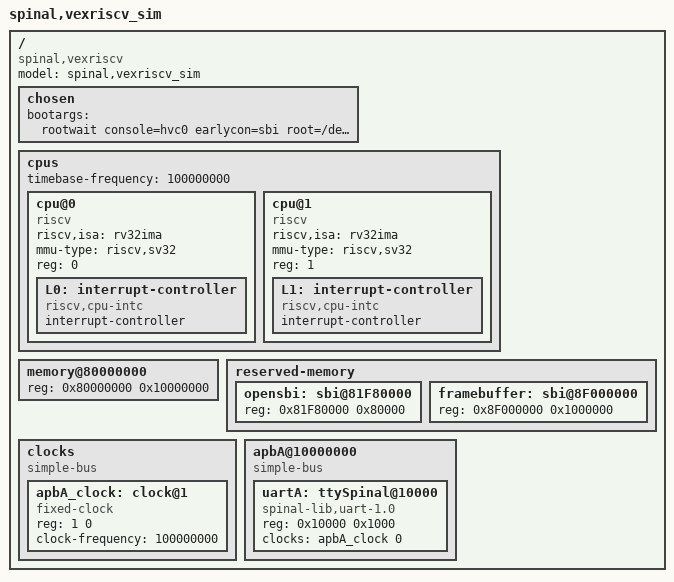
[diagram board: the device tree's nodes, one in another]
/dts-v1/;
#include <dt-bindings/gpio/gpio.h>
#include <dt-bindings/input/input.h>
#include <dt-bindings/interrupt-controller/irq.h>

/ {
    #address-cells = <0x1>;
    #size-cells = <0x1>;
    compatible = "spinal,vexriscv";
    model = "spinal,vexriscv_sim";

    chosen {
        bootargs = "rootwait console=hvc0  earlycon=sbi root=/dev/mmcblk0p2 init=/sbin/init mmc_core.use_spi_crc=0 loglevel=7";  //ignore_loglevel rng_core.default_quality=1000 random.trust_cpu=on
    };

    cpus {
        #address-cells = <0x1>;
        #size-cells = <0x0>;
        timebase-frequency = <100000000>;
        cpu@0 {
            device_type = "cpu";
            compatible = "riscv";
            riscv,isa = "rv32ima";
            mmu-type = "riscv,sv32";
            reg = <0>;
            status = "okay";
            L0: interrupt-controller {
                #interrupt-cells = <0x00000001>;
                interrupt-controller;
                compatible = "riscv,cpu-intc";
            };
        };
        cpu@1 {
            device_type = "cpu";
            compatible = "riscv";
            riscv,isa = "rv32ima";
            mmu-type = "riscv,sv32";
            reg = <1>;
            status = "okay";
            L1: interrupt-controller {
                #interrupt-cells = <0x00000001>;
                interrupt-controller;
                compatible = "riscv,cpu-intc";
            };
        };

        /*cpu@2 {
            device_type = "cpu";
            compatible = "riscv";
            riscv,isa = "rv32ima";
            mmu-type = "riscv,sv32";
            reg = <2>;
            status = "okay";
            L2: interrupt-controller {
                #interrupt-cells = <0x00000001>;
                interrupt-controller;
                compatible = "riscv,cpu-intc";
            };
        };

        cpu@3 {
            device_type = "cpu";
            compatible = "riscv";
            riscv,isa = "rv32ima";
            mmu-type = "riscv,sv32";
            reg = <3>;
            status = "okay";
            L3: interrupt-controller {
                #interrupt-cells = <0x00000001>;
                interrupt-controller;
                compatible = "riscv,cpu-intc";
            };
        };*/
    };



    memory@80000000 {
        device_type = "memory";
        reg = <0x80000000 0x10000000>;
    };



    reserved-memory {
        #address-cells = <1>;
        #size-cells = <1>;
        ranges;

        opensbi: sbi@81F80000 {
            reg = <0x81F80000 0x80000>;
        };
        framebuffer: sbi@8F000000 {
            reg = <0x8F000000 0x1000000>;
        };
    };

    clocks {
        compatible = "simple-bus";
        #address-cells = <1>;
        #size-cells = <0>;

        apbA_clock: clock@1 {
            compatible = "fixed-clock";
            reg = <1 0>;
            #clock-cells = <0>;
            clock-frequency = <100000000>;
        };
    };


    apbA@10000000 {
        compatible = "simple-bus";
        #address-cells = <0x1>;
        #size-cells = <0x1>;
        ranges = <0x0 0x10000000 0x01000000>;


        uartA: ttySpinal@10000 {
                compatible = "spinal-lib,uart-1.0";
                reg = <0x10000 0x1000>;
                clocks = <&apbA_clock 0>;
        };

    };

   
};


